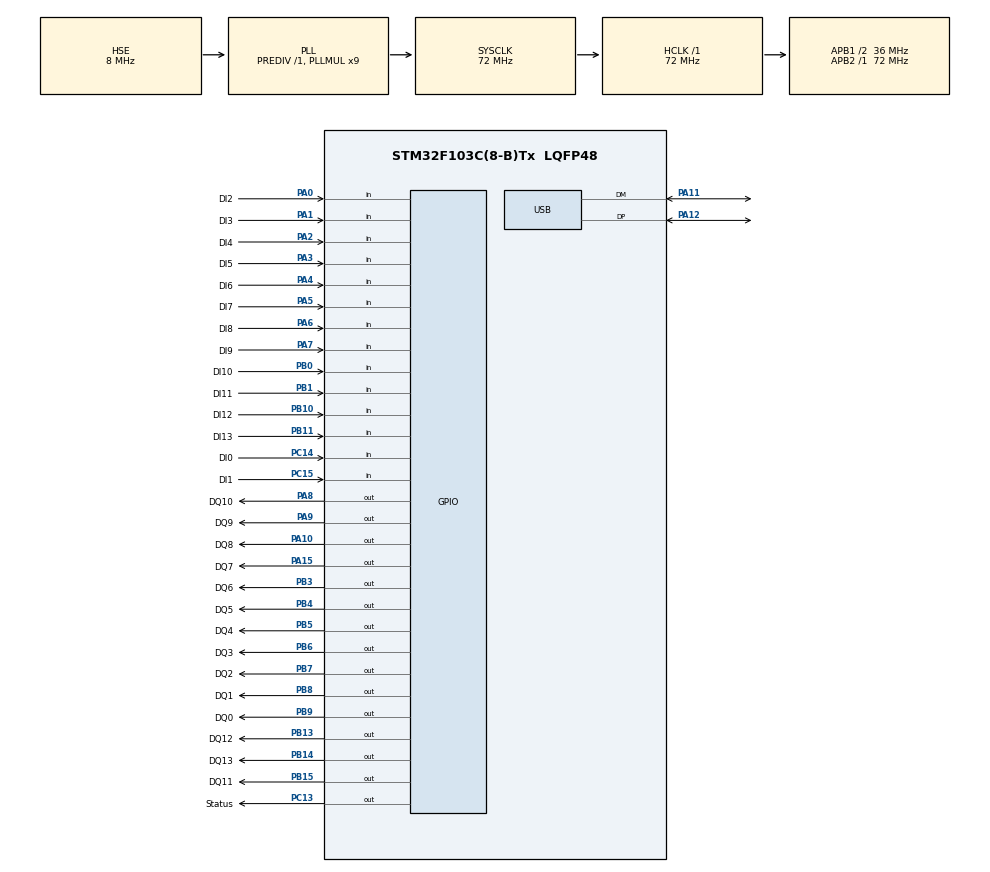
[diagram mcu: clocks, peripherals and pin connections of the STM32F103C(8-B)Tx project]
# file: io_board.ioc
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Mcu.Family=STM32F1
Mcu.Name=STM32F103C(8-B)Tx
Mcu.Package=LQFP48
NVIC.PriorityGroup=NVIC_PRIORITYGROUP_4
NVIC.USB_LP_CAN1_RX0_IRQn=true\:0\:0\:false\:false\:true\:false\:true
PA0-WKUP.GPIO_Label=DI2
PA0-WKUP.GPIO_PuPd=GPIO_PULLDOWN
PA0-WKUP.Signal=GPIO_Input
PA1.GPIO_Label=DI3
PA1.GPIO_PuPd=GPIO_PULLDOWN
PA1.Signal=GPIO_Input
PA10.GPIO_Label=DQ8
PA10.Signal=GPIO_Output
PA11.Mode=Device
PA11.Signal=USB_DM
PA12.Mode=Device
PA12.Signal=USB_DP
PA13.Mode=Serial_Wire
PA13.Signal=SYS_JTMS-SWDIO
PA14.Mode=Serial_Wire
PA14.Signal=SYS_JTCK-SWCLK
PA15.GPIO_Label=DQ7
PA15.Signal=GPIO_Output
PA2.GPIO_Label=DI4
PA2.GPIO_PuPd=GPIO_PULLDOWN
PA2.Signal=GPIO_Input
PA3.GPIO_Label=DI5
PA3.GPIO_PuPd=GPIO_PULLDOWN
PA3.Signal=GPIO_Input
PA4.GPIO_Label=DI6
PA4.GPIO_PuPd=GPIO_PULLDOWN
PA4.Signal=GPIO_Input
PA5.GPIO_Label=DI7
PA5.GPIO_PuPd=GPIO_PULLDOWN
PA5.Signal=GPIO_Input
PA6.GPIO_Label=DI8
PA6.GPIO_PuPd=GPIO_PULLDOWN
PA6.Signal=GPIO_Input
PA7.GPIO_Label=DI9
PA7.GPIO_PuPd=GPIO_PULLDOWN
PA7.Signal=GPIO_Input
PA8.GPIO_Label=DQ10
PA8.Signal=GPIO_Output
PA9.GPIO_Label=DQ9
PA9.Signal=GPIO_Output
PB0.GPIO_Label=DI10
PB0.GPIO_PuPd=GPIO_PULLDOWN
PB0.Signal=GPIO_Input
PB1.GPIO_Label=DI11
PB1.GPIO_PuPd=GPIO_PULLDOWN
PB1.Signal=GPIO_Input
PB10.GPIO_Label=DI12
PB10.GPIO_PuPd=GPIO_PULLDOWN
PB10.Signal=GPIO_Input
PB11.GPIO_Label=DI13
PB11.GPIO_PuPd=GPIO_PULLDOWN
PB11.Signal=GPIO_Input
PB13.GPIO_Label=DQ12
PB13.Signal=GPIO_Output
PB14.GPIO_Label=DQ13
PB14.Signal=GPIO_Output
PB15.GPIO_Label=DQ11
PB15.Signal=GPIO_Output
PB3.GPIO_Label=DQ6
PB3.Signal=GPIO_Output
PB4.GPIO_Label=DQ5
PB4.Signal=GPIO_Output
PB5.GPIO_Label=DQ4
PB5.Signal=GPIO_Output
PB6.GPIO_Label=DQ3
PB6.Signal=GPIO_Output
PB7.GPIO_Label=DQ2
PB7.Signal=GPIO_Output
PB8.GPIO_Label=DQ1
PB8.Signal=GPIO_Output
PB9.GPIO_Label=DQ0
PB9.Signal=GPIO_Output
PC13-TAMPER-RTC.GPIO_Label=Status
PC13-TAMPER-RTC.Signal=GPIO_Output
PC14-OSC32_IN.GPIO_Label=DI0
PC14-OSC32_IN.GPIO_PuPd=GPIO_PULLDOWN
PC14-OSC32_IN.Signal=GPIO_Input
PC15-OSC32_OUT.GPIO_Label=DI1
PC15-OSC32_OUT.GPIO_PuPd=GPIO_PULLDOWN
PC15-OSC32_OUT.Signal=GPIO_Input
PD0-OSC_IN.Mode=HSE-External-Oscillator
PD0-OSC_IN.Signal=RCC_OSC_IN
PD1-OSC_OUT.Mode=HSE-External-Oscillator
PD1-OSC_OUT.Signal=RCC_OSC_OUT
ProjectManager.HeapSize=0x200
ProjectManager.StackSize=0x400
ProjectManager.TargetToolchain=Other Toolchains (GPDSC)
RCC.AHBFreq_Value=72000000
RCC.APB1CLKDivider=RCC_HCLK_DIV2
RCC.APB1Freq_Value=36000000
RCC.APB1TimFreq_Value=72000000
RCC.APB2Freq_Value=72000000
RCC.APB2TimFreq_Value=72000000
RCC.HCLKFreq_Value=72000000
RCC.PLLMUL=RCC_PLL_MUL9
RCC.PLLSourceVirtual=RCC_PLLSOURCE_HSE
RCC.SYSCLKFreq_VALUE=72000000
RCC.SYSCLKSource=RCC_SYSCLKSOURCE_PLLCLK
RCC.USBFreq_Value=48000000
RCC.USBPrescaler=RCC_USBCLKSOURCE_PLL_DIV1_5
USB_DEVICE.CLASS_NAME_FS=CDC
USB_DEVICE.MANUFACTURER_STRING=SmartSolutionsDebrecen
USB_DEVICE.PRODUCT_STRING_CDC_FS=IO Board
USB_DEVICE.VirtualMode=Cdc
USB_DEVICE.VirtualModeFS=Cdc_FS
VP_USB_DEVICE_VS_USB_DEVICE_CDC_FS.Mode=CDC_FS
board=custom

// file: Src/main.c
/* USER CODE BEGIN Header */
/**
  ******************************************************************************
  * @file           : main.c
  * @brief          : Main program body
  ******************************************************************************
  * @attention
  *
  * <h2><center>&copy; Copyright (c) 2020 STMicroelectronics.
  * All rights reserved.</center></h2>
  *
  * This software component is licensed by ST under Ultimate Liberty license
  * SLA0044, the "License"; You may not use this file except in compliance with
  * the License. You may obtain a copy of the License at:
  *                             www.st.com/SLA0044
  *
  ******************************************************************************
  */
/* USER CODE END Header */
#include "main.h"
#include "usb_device.h"

/* USER CODE BEGIN Includes */
#include "def.h"
/* USER CODE END Includes */

void SystemClock_Config(void);
static void MX_GPIO_Init(void);

/* USER CODE BEGIN 0 */
extern USBD_HandleTypeDef hUsbDeviceFS;
/* USER CODE END 0 */

int main(void)
{

  /* MCU Configuration--------------------------------------------------------*/

  /* Reset of all peripherals, Initializes the Flash interface and the Systick. */
  HAL_Init();

  /* Configure the system clock */
  SystemClock_Config();

  /* Initialize all configured peripherals */
  MX_GPIO_Init();
  MX_USB_DEVICE_Init();

  /* Infinite loop */
    while (1)
    {

    /* USER CODE BEGIN 3 */
        while (hUsbDeviceFS.dev_state != USBD_STATE_CONFIGURED)
        {
            StatusH;
            HAL_Delay(250);
            StatusL;
            HAL_Delay(250);
        }
    }
  /* USER CODE END 3 */
}

void SystemClock_Config(void)
{
  RCC_OscInitTypeDef RCC_OscInitStruct = {0};
  RCC_ClkInitTypeDef RCC_ClkInitStruct = {0};
  RCC_PeriphCLKInitTypeDef PeriphClkInit = {0};

  /** Initializes the RCC Oscillators according to the specified parameters
  * in the RCC_OscInitTypeDef structure.
  */
  RCC_OscInitStruct.OscillatorType = RCC_OSCILLATORTYPE_HSE;
  RCC_OscInitStruct.HSEState = RCC_HSE_ON;
  RCC_OscInitStruct.HSEPredivValue = RCC_HSE_PREDIV_DIV1;
  RCC_OscInitStruct.HSIState = RCC_HSI_ON;
  RCC_OscInitStruct.PLL.PLLState = RCC_PLL_ON;
  RCC_OscInitStruct.PLL.PLLSource = RCC_PLLSOURCE_HSE;
  RCC_OscInitStruct.PLL.PLLMUL = RCC_PLL_MUL9;
  if (HAL_RCC_OscConfig(&RCC_OscInitStruct) != HAL_OK)
  {
    Error_Handler();
  }
  /** Initializes the CPU, AHB and APB buses clocks
  */
  RCC_ClkInitStruct.ClockType = RCC_CLOCKTYPE_HCLK|RCC_CLOCKTYPE_SYSCLK
                              |RCC_CLOCKTYPE_PCLK1|RCC_CLOCKTYPE_PCLK2;
  RCC_ClkInitStruct.SYSCLKSource = RCC_SYSCLKSOURCE_PLLCLK;
  RCC_ClkInitStruct.AHBCLKDivider = RCC_SYSCLK_DIV1;
  RCC_ClkInitStruct.APB1CLKDivider = RCC_HCLK_DIV2;
  RCC_ClkInitStruct.APB2CLKDivider = RCC_HCLK_DIV1;

  if (HAL_RCC_ClockConfig(&RCC_ClkInitStruct, FLASH_LATENCY_2) != HAL_OK)
  {
    Error_Handler();
  }
  PeriphClkInit.PeriphClockSelection = RCC_PERIPHCLK_USB;
  PeriphClkInit.UsbClockSelection = RCC_USBCLKSOURCE_PLL_DIV1_5;
  if (HAL_RCCEx_PeriphCLKConfig(&PeriphClkInit) != HAL_OK)
  {
    Error_Handler();
  }
}

static void MX_GPIO_Init(void)
{
  GPIO_InitTypeDef GPIO_InitStruct = {0};

  /* GPIO Ports Clock Enable */
  __HAL_RCC_GPIOC_CLK_ENABLE();
  __HAL_RCC_GPIOD_CLK_ENABLE();
  __HAL_RCC_GPIOA_CLK_ENABLE();
  __HAL_RCC_GPIOB_CLK_ENABLE();

  /*Configure GPIO pin Output Level */
  HAL_GPIO_WritePin(Status_GPIO_Port, Status_Pin, GPIO_PIN_RESET);

  /*Configure GPIO pin Output Level */
  HAL_GPIO_WritePin(GPIOB, DQ12_Pin|DQ13_Pin|DQ11_Pin|DQ6_Pin
                          |DQ5_Pin|DQ4_Pin|DQ3_Pin|DQ2_Pin
                          |DQ1_Pin|DQ0_Pin, GPIO_PIN_RESET);

  /*Configure GPIO pin Output Level */
  HAL_GPIO_WritePin(GPIOA, DQ10_Pin|DQ9_Pin|DQ8_Pin|DQ7_Pin, GPIO_PIN_RESET);

  /*Configure GPIO pin : Status_Pin */
  GPIO_InitStruct.Pin = Status_Pin;
  GPIO_InitStruct.Mode = GPIO_MODE_OUTPUT_PP;
  GPIO_InitStruct.Pull = GPIO_NOPULL;
  GPIO_InitStruct.Speed = GPIO_SPEED_FREQ_LOW;
  HAL_GPIO_Init(Status_GPIO_Port, &GPIO_InitStruct);

  /*Configure GPIO pins : DI0_Pin DI1_Pin */
  GPIO_InitStruct.Pin = DI0_Pin|DI1_Pin;
  GPIO_InitStruct.Mode = GPIO_MODE_INPUT;
  GPIO_InitStruct.Pull = GPIO_PULLDOWN;
  HAL_GPIO_Init(GPIOC, &GPIO_InitStruct);

  /*Configure GPIO pins : DI2_Pin DI3_Pin DI4_Pin DI5_Pin
                           DI6_Pin DI7_Pin DI8_Pin DI9_Pin */
  GPIO_InitStruct.Pin = DI2_Pin|DI3_Pin|DI4_Pin|DI5_Pin
                          |DI6_Pin|DI7_Pin|DI8_Pin|DI9_Pin;
  GPIO_InitStruct.Mode = GPIO_MODE_INPUT;
  GPIO_InitStruct.Pull = GPIO_PULLDOWN;
  HAL_GPIO_Init(GPIOA, &GPIO_InitStruct);

  /*Configure GPIO pins : DI10_Pin DI11_Pin DI12_Pin DI13_Pin */
  GPIO_InitStruct.Pin = DI10_Pin|DI11_Pin|DI12_Pin|DI13_Pin;
  GPIO_InitStruct.Mode = GPIO_MODE_INPUT;
  GPIO_InitStruct.Pull = GPIO_PULLDOWN;
  HAL_GPIO_Init(GPIOB, &GPIO_InitStruct);

  /*Configure GPIO pins : DQ12_Pin DQ13_Pin DQ11_Pin DQ6_Pin
                           DQ5_Pin DQ4_Pin DQ3_Pin DQ2_Pin
                           DQ1_Pin DQ0_Pin */
  GPIO_InitStruct.Pin = DQ12_Pin|DQ13_Pin|DQ11_Pin|DQ6_Pin
                          |DQ5_Pin|DQ4_Pin|DQ3_Pin|DQ2_Pin
                          |DQ1_Pin|DQ0_Pin;
  GPIO_InitStruct.Mode = GPIO_MODE_OUTPUT_PP;
  GPIO_InitStruct.Pull = GPIO_NOPULL;
  GPIO_InitStruct.Speed = GPIO_SPEED_FREQ_LOW;
  HAL_GPIO_Init(GPIOB, &GPIO_InitStruct);

  /*Configure GPIO pins : DQ10_Pin DQ9_Pin DQ8_Pin DQ7_Pin */
  GPIO_InitStruct.Pin = DQ10_Pin|DQ9_Pin|DQ8_Pin|DQ7_Pin;
  GPIO_InitStruct.Mode = GPIO_MODE_OUTPUT_PP;
  GPIO_InitStruct.Pull = GPIO_NOPULL;
  GPIO_InitStruct.Speed = GPIO_SPEED_FREQ_LOW;
  HAL_GPIO_Init(GPIOA, &GPIO_InitStruct);

}

void Error_Handler(void)
{
}

/************************ (C) COPYRIGHT STMicroelectronics *****END OF FILE****/
